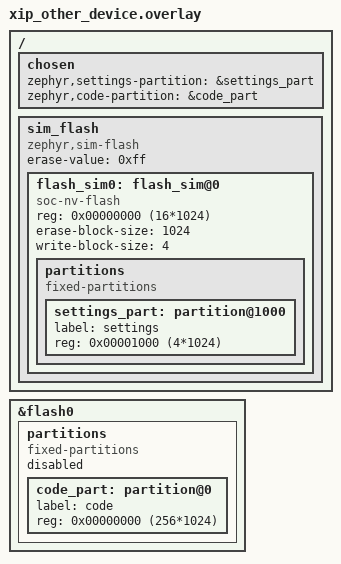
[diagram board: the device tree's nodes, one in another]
/* SPDX-License-Identifier: Apache-2.0 */

/*
 * XIP target where the firmware runs from a different flash device than the
 * settings partition. The partition offset (relative to its own device)
 * numerically falls inside the image address range, but the device differs,
 * so bacnet_storage_erase() must not refuse the erase.
 * The flash is a RAM-backed simulator, so nothing real can be erased.
 */
/ {
  chosen {
    zephyr,settings-partition = &settings_part;
    zephyr,code-partition = &code_part;
  };

  sim_flash: sim_flash {
    compatible = "zephyr,sim-flash";
    #address-cells = <1>;
    #size-cells = <1>;
    erase-value = <0xff>;

    flash_sim0: flash_sim@0 {
      compatible = "soc-nv-flash";
      reg = <0x00000000 (16*1024)>;
      erase-block-size = <1024>;
      write-block-size = <4>;

      partitions {
        compatible = "fixed-partitions";
        #address-cells = <1>;
        #size-cells = <1>;

        settings_part: partition@1000 {
          label = "settings";
          reg = <0x00001000 (4*1024)>;
        };
      };
    };
  };
};

/* The firmware flash has no driver here; its partition table is only
   used to identify the device, so it must stay disabled. */
&flash0 {
  partitions {
    compatible = "fixed-partitions";
    status = "disabled";
    #address-cells = <1>;
    #size-cells = <1>;

    code_part: partition@0 {
      label = "code";
      reg = <0x00000000 (256*1024)>;
    };
  };
};
